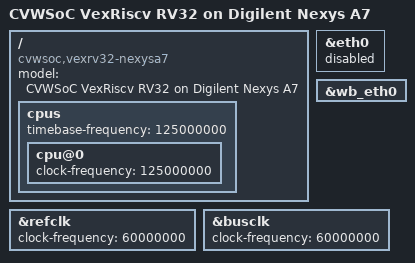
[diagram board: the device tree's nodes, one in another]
/dts-v1/;

/include/ "cvwsoc-cpu-vexrv32.dtsi"
/include/ "cvwsoc.dtsi"
/include/ "cvwsoc-board-nexysa7.dtsi"

/ {
  model = "CVWSoC VexRiscv RV32 on Digilent Nexys A7";
  compatible = "cvwsoc,vexrv32-nexysa7", "cvwsoc,cvwsoc";

  cpus {
    timebase-frequency = <125000000>;
    cpu@0 {
      clock-frequency = <125000000>;
    };
  };


};

&eth0 { status = "disabled"; };
&wb_eth0 { status = "okay"; };

&refclk { clock-frequency = <60000000>; };
&busclk { clock-frequency = <60000000>; };
